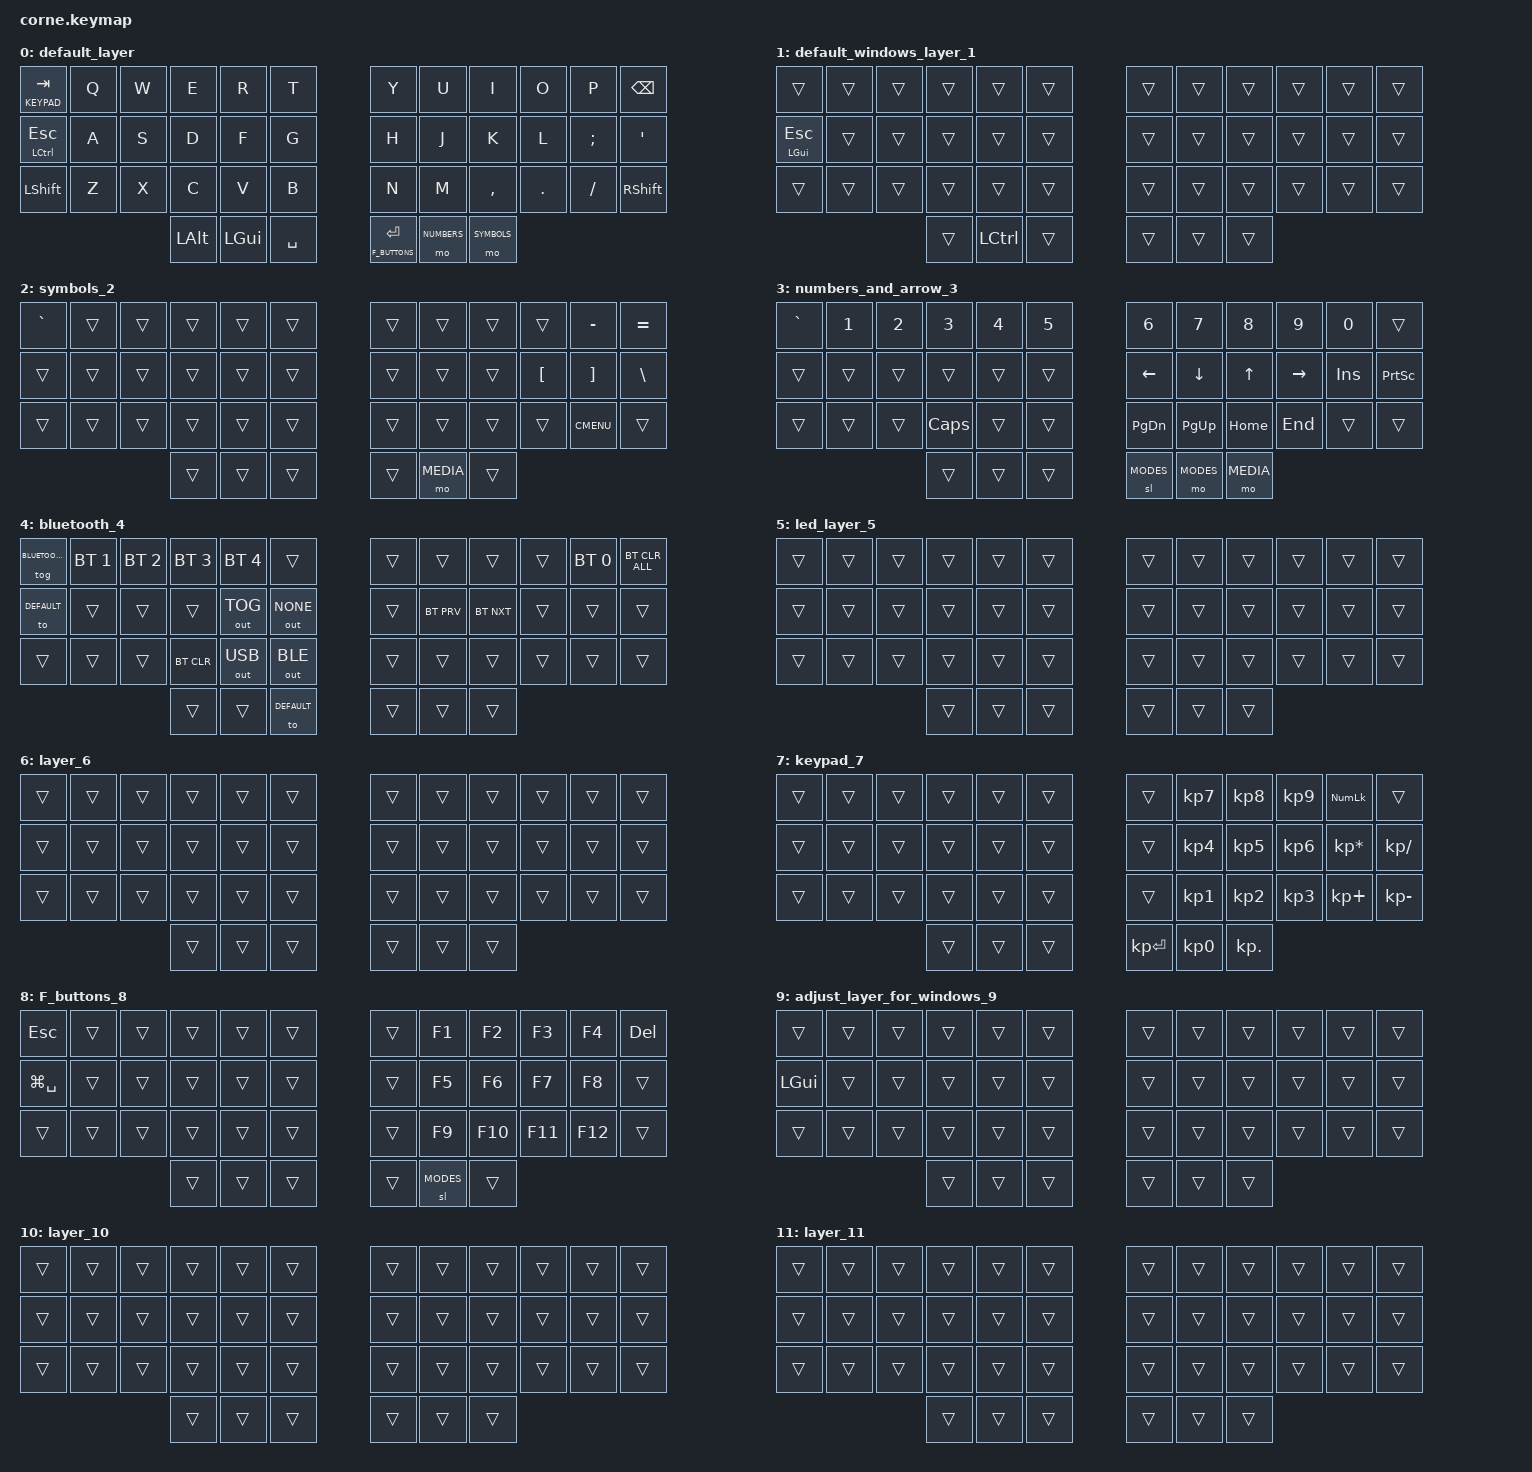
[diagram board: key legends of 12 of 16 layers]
/*
 * Copyright (c) 2020 The ZMK Contributors
 *
 * SPDX-License-Identifier: MIT
 */

#include <behaviors.dtsi>
#include <dt-bindings/zmk/keys.h>
#include <dt-bindings/zmk/bt.h>
#include <dt-bindings/zmk/outputs.h>

#define DEFAULT 0
#define WINDOWS 1
#define SYMBOLS 2
#define NUMBERS 3
#define BLUETOOTH 4
#define LED 5
#define KEYPAD 7
#define F_BUTTONS 8
#define ADJUST_LAYER_FOR_WINDOWS 9
#define GAME0 12
#define GAME1 13
#define MEDIA 14
#define MODES 15


&sl {
    release-after-ms = <5000>;
};

/ {
        keymap {
                compatible = "zmk,keymap";

                default_layer {
                        bindings = <
&lt KEYPAD TAB  &kp Q  &kp W  &kp E     &kp R    &kp T          &kp Y              &kp U        &kp I        &kp O    &kp P     &kp BSPC
&mt LCTL ESC    &kp A  &kp S  &kp D     &kp F    &kp G          &kp H              &kp J        &kp K        &kp L    &kp SEMI  &kp SQT
&kp LSHFT       &kp Z  &kp X  &kp C     &kp V    &kp B          &kp N              &kp M        &kp COMMA    &kp DOT  &kp FSLH  &kp RSHFT
                              &kp LALT  &kp LGUI &kp SPACE      &lt F_BUTTONS RET  &mo NUMBERS  &mo SYMBOLS
                        >;
                };

                default_windows_layer_1 {
                        bindings = <
&trans        &trans  &trans  &trans  &trans    &trans     &trans  &trans  &trans  &trans  &trans  &trans
&mt LGUI ESC  &trans  &trans  &trans  &trans    &trans     &trans  &trans  &trans  &trans  &trans  &trans
&trans        &trans  &trans  &trans  &trans    &trans     &trans  &trans  &trans  &trans  &trans  &trans
                              &trans  &kp LCTL  &trans     &trans  &trans  &trans
                        >;
                };

                symbols_2 {
                        bindings = <
&kp GRAVE   &trans  &trans  &trans  &trans  &trans      &trans  &trans     &trans  &trans    &kp MINUS    &kp EQUAL
&trans      &trans  &trans  &trans  &trans  &trans      &trans  &trans     &trans  &kp LBKT  &kp RBKT     &kp BSLH
&trans      &trans  &trans  &trans  &trans  &trans      &trans  &trans     &trans  &trans    &kp K_CMENU  &trans
                            &trans  &trans  &trans      &trans  &mo MEDIA  &trans
                        >;
                };

                numbers_and_arrow_3 {
                        bindings = <
&kp GRAVE   &kp N1 &kp N2 &kp N3   &kp N4 &kp N5         &kp N6    &kp N7    &kp N8    &kp N9    &kp N0  &trans
&trans       &trans &trans &trans   &trans &trans         &kp LEFT  &kp DOWN  &kp UP    &kp RIGHT &kp INS &kp PRINTSCREEN
&trans       &trans &trans &kp CAPS &trans &trans         &kp PG_DN &kp PG_UP &kp HOME  &kp END   &trans  &trans
                           &trans   &trans &trans         &sl MODES &mo MODES &mo MEDIA
                        >;
                };

                bluetooth_4 {
                        bindings = <
&tog BLUETOOTH   &bt BT_SEL 1  &bt BT_SEL 2  &bt BT_SEL 3  &bt BT_SEL 4  &trans            &trans  &trans      &trans      &trans  &bt BT_SEL 0  &bt BT_CLR_ALL
&to DEFAULT      &trans        &trans        &trans        &out OUT_TOG  &out OUT_NONE     &trans  &bt BT_PRV  &bt BT_NXT  &trans  &trans        &trans
&trans           &trans        &trans        &bt BT_CLR    &out OUT_USB  &out OUT_BLE      &trans  &trans      &trans      &trans  &trans        &trans
                                             &trans        &trans        &to DEFAULT       &trans  &trans      &trans
                        >;
                };

                led_layer_5 {
                        bindings = <
&trans  &trans  &trans  &trans  &trans  &trans     &trans  &trans  &trans  &trans  &trans  &trans
&trans  &trans  &trans  &trans  &trans  &trans     &trans  &trans  &trans  &trans  &trans  &trans
&trans  &trans  &trans  &trans  &trans  &trans     &trans  &trans  &trans  &trans  &trans  &trans
                        &trans  &trans  &trans     &trans  &trans  &trans
                        >;
                };

                layer_6 {
                        bindings = <
&trans  &trans  &trans  &trans  &trans  &trans     &trans  &trans  &trans  &trans  &trans  &trans
&trans  &trans  &trans  &trans  &trans  &trans     &trans  &trans  &trans  &trans  &trans  &trans
&trans  &trans  &trans  &trans  &trans  &trans     &trans  &trans  &trans  &trans  &trans  &trans
                        &trans  &trans  &trans     &trans  &trans  &trans
                        >;
                };

                keypad_7 {
                        bindings = <
&trans  &trans  &trans  &trans  &trans  &trans     &trans        &kp KP_N7  &kp KP_N8  &kp KP_N9  &kp KP_NUMLOCK    &trans
&trans  &trans  &trans  &trans  &trans  &trans     &trans        &kp KP_N4  &kp KP_N5  &kp KP_N6  &kp KP_ASTERISK   &kp KP_SLASH
&trans  &trans  &trans  &trans  &trans  &trans     &trans        &kp KP_N1  &kp KP_N2  &kp KP_N3  &kp KP_PLUS       &kp KP_SUBTRACT
                        &trans  &trans  &trans     &kp KP_ENTER  &kp KP_N0  &kp KP_DOT
                        >;
                };

                F_buttons_8 {
                        bindings = <
&kp ESC        &trans  &trans  &trans  &trans  &trans     &trans  &kp F1     &kp F2   &kp F3   &kp F4   &kp DEL
&kp LG(SPACE)  &trans  &trans  &trans  &trans  &trans     &trans  &kp F5     &kp F6   &kp F7   &kp F8   &trans
&trans         &trans  &trans  &trans  &trans  &trans     &trans  &kp F9     &kp F10  &kp F11  &kp F12  &trans
                               &trans  &trans  &trans     &trans  &sl MODES  &trans
                        >;
                };

                adjust_layer_for_windows_9 {
                        bindings = <
&trans    &trans  &trans  &trans  &trans  &trans     &trans  &trans  &trans  &trans  &trans  &trans
&kp LGUI  &trans  &trans  &trans  &trans  &trans     &trans  &trans  &trans  &trans  &trans  &trans
&trans    &trans  &trans  &trans  &trans  &trans     &trans  &trans  &trans  &trans  &trans  &trans
                          &trans  &trans  &trans     &trans  &trans  &trans
                        >;
                };

                layer_10 {
                        bindings = <
&trans  &trans  &trans  &trans  &trans  &trans     &trans  &trans  &trans  &trans  &trans  &trans
&trans  &trans  &trans  &trans  &trans  &trans     &trans  &trans  &trans  &trans  &trans  &trans
&trans  &trans  &trans  &trans  &trans  &trans     &trans  &trans  &trans  &trans  &trans  &trans
                        &trans  &trans  &trans     &trans  &trans  &trans
                        >;
                };

                layer_11 {
                        bindings = <
&trans  &trans  &trans  &trans  &trans  &trans     &trans  &trans  &trans  &trans  &trans  &trans
&trans  &trans  &trans  &trans  &trans  &trans     &trans  &trans  &trans  &trans  &trans  &trans
&trans  &trans  &trans  &trans  &trans  &trans     &trans  &trans  &trans  &trans  &trans  &trans
                        &trans  &trans  &trans     &trans  &trans  &trans
                        >;
                };

                game0_12 {
                        bindings = <
&kp TAB  &trans  &trans  &trans    &trans    &trans        &trans     &trans   &trans     &trans  &trans  &trans
&kp CAPS &trans  &trans  &trans    &trans    &trans        &trans     &trans   &trans     &trans  &trans  &trans
&trans   &trans  &trans  &trans    &trans    &trans        &trans     &trans   &trans     &trans  &trans  &trans
                         &kp LALT  &kp LCTL  &kp SPACE     &mo GAME1  &kp RET  &mo MEDIA
                        >;
                };


                game1_13 {
                        bindings = <
&trans   &trans  &trans  &trans    &trans  &trans      &kp KP_N7  &kp KP_N8  &kp KP_N9  &trans    &kp UP    &trans
&kp ESC  &trans  &trans  &trans    &trans  &trans      &kp KP_N4  &kp KP_N5  &kp KP_N6  &kp LEFT  &kp DOWN  &kp RIGHT
&trans   &trans  &trans  &trans    &trans  &trans      &kp KP_N1  &kp KP_N2  &kp KP_N3  &trans    &trans    &trans
                         &kp LGUI  &trans  &trans      &trans     &kp ESC    &sl MODES
                        >;
                };

                media_14 {
                        bindings = <
&trans  &trans  &trans  &trans  &trans  &trans     &trans  &trans      &trans      &kp C_VOLUME_DOWN  &kp C_VOLUME_UP   &kp C_MUTE
&trans  &trans  &trans  &trans  &trans  &trans     &trans  &kp C_PREV  &kp C_NEXT  &kp UP             &kp C_PLAY_PAUSE  &trans
&trans  &trans  &trans  &trans  &trans  &trans     &trans  &trans      &kp LEFT    &kp DOWN           &kp RIGHT         &trans
                        &trans  &trans  &trans     &trans  &trans      &trans
                        >;
                };

                modes_15 {
                        bindings = <
&trans      &trans &to WINDOWS &trans &trans &trans            &trans      &trans &trans &trans &trans &trans
&to DEFAULT &trans &trans      &trans &trans &to GAME0         &trans      &trans &trans &trans &trans &trans
&trans      &trans &trans      &trans &trans &to BLUETOOTH     &to NUMBERS &trans &trans &trans &trans &trans
                               &trans &trans &to DEFAULT       &trans      &trans &trans
                        >;
                };

        };
        conditional_layers {
                compatible = "zmk,conditional-layers";
                adjustment_for_windows {
                        if-layers = <WINDOWS F_BUTTONS>;
                        then-layer = <ADJUST_LAYER_FOR_WINDOWS>;
                };
        };
};
